# cslr_emac register map
Vendor: Texas Instruments
Peripheral module from a debugger description file (folder tci6486).
Registers are 32-bit, read-write, reset 0x0 unless marked. A register's access mark holds for its fields unless they carry their own. Offsets are as the file gives them; lines under a group give offsets from that group; [hi:lo] are bit positions; {n}, {i} and the like mark numbered series; 'fields as' and 'values as' point back to an identical list; <NAME> marks a mode.

## EMAC — Ethernet Media Access Controller
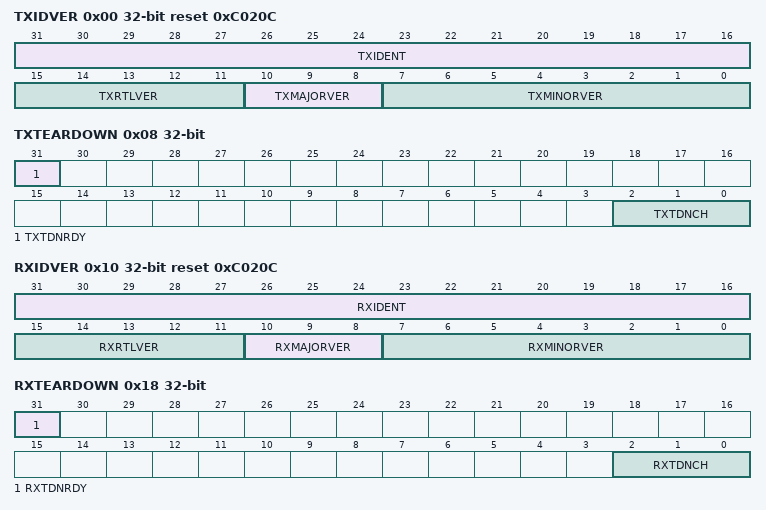
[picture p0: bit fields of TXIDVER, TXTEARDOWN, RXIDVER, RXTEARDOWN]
0x00 TXIDVER ro reset 0xC020C — Transmit Identification and Version Register
  [31:16] TXIDENT — Transmit identification value
  [15:11] TXRTLVER — Transmit RTL version value
  [10:8] TXMAJORVER — Transmit major version value
  [7:0] TXMINORVER — Transmit minor version value
0x04 TXCONTROL access not given — Transmit Control Register
  [0] TXEN rw — Transmit enable
    0=DISABLE (Transmit is disabled); 1=ENABLE (Transmit is enabled)
0x08 TXTEARDOWN access not given — Transmit Teardown Register
  [31] TXTDNRDY ro — Transmit Teardown Ready  read as zero but always assumed to be one (unused).
  [2:0] TXTDNCH rw — Transmit teardown channel. Transmit channel teardown is commanded by writing the encoded value of the transmit channel to be torn down. The teardown register is read as zero.
    {v}=CHA{v} (Teardown transmit channel {v}) (v=0..7)
0x10 RXIDVER ro reset 0xC020C — Receive Identification and Version Register
  [31:16] RXIDENT — Receive identification value
  [15:11] RXRTLVER — Receive RTL version value
  [10:8] RXMAJORVER — Receive major version value
  [7:0] RXMINORVER — Receive minor version value
0x14 RXCONTROL access not given — Receive Control Register
  [0] RXEN rw — Receive DMA enable
    0=DISABLE (Receive is disabled); 1=ENABLE (Receive is enabled)
0x18 RXTEARDOWN access not given — Receive Teardown Register
  [31] RXTDNRDY ro — Receive Teardown Ready. Read as zero, but always assumed to be one (unused)
  [2:0] RXTDNCH rw — Receive teardown channel. Receive channel teardown is commanded by writing the encoded value of the receive channel to be torn down. The teardown register is read as zero.
    {v}=CHA{v} (Teardown receive channel {v}) (v=0..7)
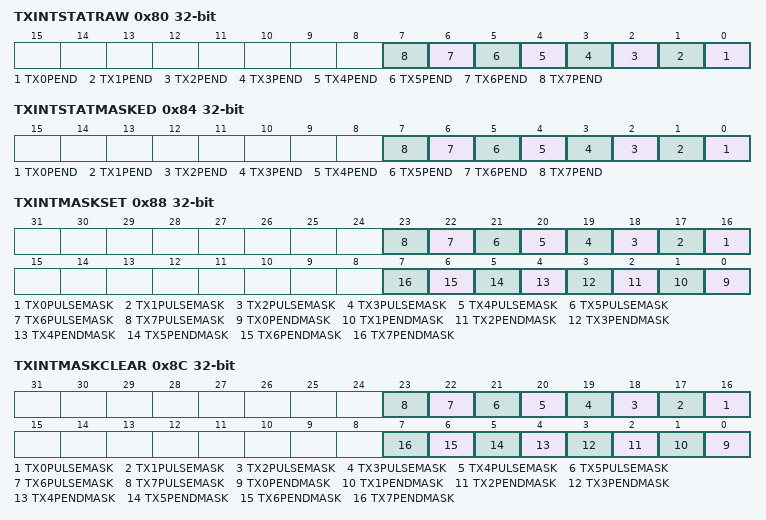
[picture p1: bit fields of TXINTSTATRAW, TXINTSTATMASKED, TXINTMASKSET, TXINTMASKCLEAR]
0x80 TXINTSTATRAW access not given — Transmit Interrupt Status (Unmasked) Register
  [n] TX{n}PEND ro (n=0..7) — TX{n}PEND raw interrupt read (before mask)
0x84 TXINTSTATMASKED access not given — Transmit Interrupt Status (Masked) Register
  [n] TX{n}PEND ro (n=0..7) — TX{n}PEND masked interrupt read
0x88 TXINTMASKSET access not given — Transmit Interrupt Mask Set Register
  [n+16] TX{n}PULSEMASK (n=0..7) — Transmit channel {n} pulse interrupt mask set bit. Write 1 to enable interrupt, a write of 0 has no effect. (access RWS)
  [n] TX{n}PENDMASK (n=0..7) — Transmit channel {n} pending interrupt mask set bit. Write 1 to enable interrupt, a write of 0 has no effect. (access RWS)
0x8C TXINTMASKCLEAR access not given — Transmit Interrupt Clear Register
  [n+16] TX{n}PULSEMASK (n=0..7) — Transmit channel {n} pulse interrupt mask clear bit. Write 1 to disable interrupt, a write of 0 has no effect. (access RWS)
  [n] TX{n}PENDMASK (n=0..7) — Transmit channel {n} pending interrupt mask clear bit. Write 1 to disable interrupt, a write of 0 has no effect. (access RWS)
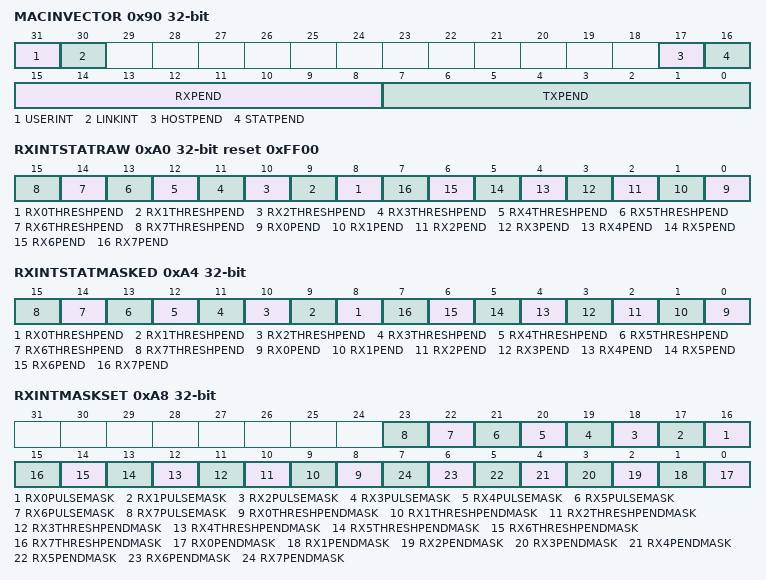
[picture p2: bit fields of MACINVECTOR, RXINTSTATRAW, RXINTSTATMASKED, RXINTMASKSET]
0x90 MACINVECTOR access not given — MAC Input Vector Register
  [31] USERINT ro — MDIO module user interrupt (USERINT) pending status bit
  [30] LINKINT ro — MDIO module link change interrupt (LINKINT) pending status bit
  [17] HOSTPEND ro — EMAC module host error interrupt (HOSTPEND) pending status bit
  [16] STATPEND ro — EMAC module statistics interrupt (STATPEND) pending status bit
  [15:8] RXPEND ro — Receive channels 0-7 interrupt (RXxPEND) pending status bit. Bit 8 is receive channel 0.
  [7:0] TXPEND ro — Transmit channels 0-7 interrupt (TXxPEND) pending status bit. Bit 0 is transmit channel 0.
0x94 MACEOIVECTOR access not given — MAC End of Interrupt Vector Register
  [4:0] MACEOIVECT rw — MAC End of Interrupt Vector  The MACEOIVECT(4:0) pins reflect the value written to this location one VBUSP_CLK cycle after write to this location. The EOI_WR signal is asserted for a single clock cycle after a a latency of two VBUSP_CLK cycle when a write is performed to this location.
0xA0 RXINTSTATRAW access not given reset 0xFF00 — Receive Interrupt Status (Unmasked) Register
  [n+8] RX{n}THRESHPEND ro (n=0..7) — RX{n}THRESHPEND raw interrupt read (before mask)
  [n] RX{n}PEND ro (n=0..7) — RX{n}PEND raw interrupt read (before mask)
0xA4 RXINTSTATMASKED access not given — Receive Interrupt Status (Masked) Register
  [n+8] RX{n}THRESHPEND ro (n=0..7) — RX{n}THRESHPEND masked interrupt read
  [n] RX{n}PEND ro (n=0..7) — RX{n}PEND masked interrupt read
0xA8 RXINTMASKSET access not given — Receive Interrupt Mask Set Register
  [n+16] RX{n}PULSEMASK (n=0..7) — Receive channel {n} Pulse Int. Mask. Write 1 to enable interrupt, a write of 0 has no effect. (access RWS)
  [n+8] RX{n}THRESHPENDMASK (n=0..7) — Receive channel {n} Threshold pending Int. Mask. Write 1 to enable interrupt, a write of 0 has no effect. (access RWS)
  [n] RX{n}PENDMASK (n=0..7) — Receive channel {n} Pending Int. Mask. Write 1 to enable interrupt, a write of 0 has no effect. (access RWS)
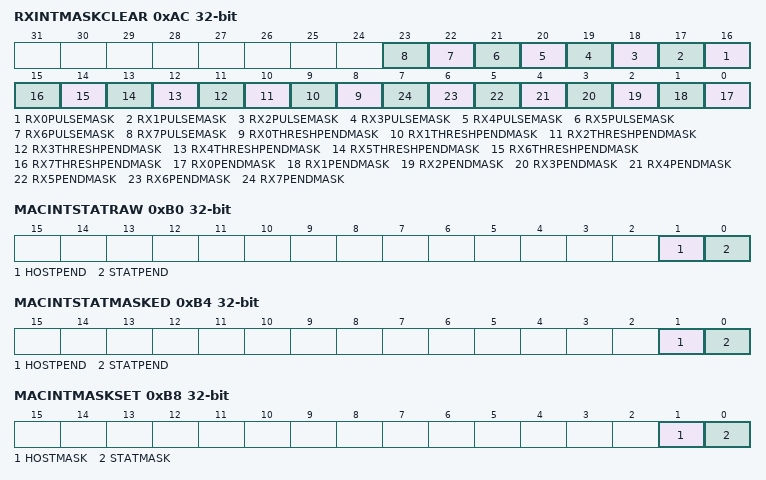
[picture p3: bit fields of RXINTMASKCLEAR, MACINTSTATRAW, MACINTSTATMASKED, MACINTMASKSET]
0xAC RXINTMASKCLEAR access not given — Receive Interrupt Mask Clear Register
  [n+16] RX{n}PULSEMASK (n=0..7) — Receive channel {n} Pulse Int. Mask. Write 1 to disable interrupt, a write of 0 has no effect. (access RWS)
  [n+8] RX{n}THRESHPENDMASK (n=0..7) — Receive channel {n} Threshold pending Int. Mask. Write 1 to disable interrupt, a write of 0 has no effect. (access RWS)
  [n] RX{n}PENDMASK (n=0..7) — Receive channel {n} Pending Int. Mask. Write 1 to disable interrupt, a write of 0 has no effect. (access RWC)
0xB0 MACINTSTATRAW access not given — MAC Interrupt Status (Unmasked) Register
  [1] HOSTPEND ro — Host pending interrupt; raw interrupt read (before mask)
  [0] STATPEND ro — Statistics pending interrupt; raw interrupt read (before mask)
0xB4 MACINTSTATMASKED access not given — MAC Interrupt Status (Masked) Register
  [1] HOSTPEND ro — Host pending interrupt; masked interrupt read
  [0] STATPEND ro — Statistics pending interrupt; masked interrupt read
0xB8 MACINTMASKSET access not given — MAC Interrupt Mask Set Register
  [1] HOSTMASK — Host error interrupt mask set bit. Write 1 to enable interrupt, a write of 0 has no effect. (access RWS)
  [0] STATMASK — Statistics interrupt mask set bit. Write 1 to enable interrupt, a write of 0 has no effect. (access RWS)
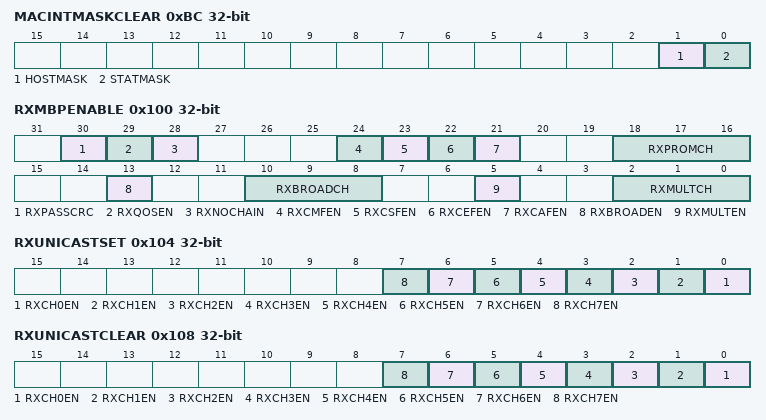
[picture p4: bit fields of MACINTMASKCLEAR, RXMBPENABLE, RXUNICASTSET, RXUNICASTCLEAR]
0xBC MACINTMASKCLEAR access not given — MAC Interrupt Mask Clear Register
  [1] HOSTMASK — Host error interrupt mask clear bit. Write 1 to disable interrupt, a write of 0 has no effect. (access RWC)
  [0] STATMASK — Statistics interrupt mask clear bit. Write 1 to disable interrupt, a write of 0 has no effect. (access RWC)
0x100 RXMBPENABLE access not given — Receive Multicast/Broadcast/Promiscuous Channel Enable Register
  [30] RXPASSCRC rw — Pass receive CRC enable bit
    0=DISCARD (Received CRC is discarded for all channels and is not included in the buffer descriptor packet length field); 1=INCLUDE (Received CRC is transferred to memory for all channels and is included in the buffer descriptor packet length)
  [29] RXQOSEN rw — Receive quality of service enable bit
    0=DISABLE (Receive QOS is disabled); 1=ENABLE (Receive QOS is enabled)
  [28] RXNOCHAIN rw — Receive no buffer chaining bit
    0=DISABLE (Received frames can span multiple buffers); 1=ENABLE (Receive DMA controller transfers each frame into a single buffer regardless of the frame or buffer size. All remaining frame data after the first buffer is discarded. The buffer descriptor)
  [24] RXCMFEN rw — Receive copy MAC control frames enable bit. Enables MAC control frames to be transferred to memory. MAC control frames are normally acted upon (if enabled), but not copied to memory. MAC control frames that are pause frames will be acted upon if enabled in MACCONTROL, regardless of the value of RXCMFEN. Frames transferred to memory due to RXCMFEN will have the CONTROL bit set in their EOP buffer descriptor.
    0=DISABLE (MAC control frames are filtered (but acted upon if enabled)); 1=ENABLE (MAC control frames are transferred to memory)
  [23] RXCSFEN rw — Receive copy short frames enable bit. Enables frames or fragments shorter than 64 bytes to be copied to memory. Frames transferred to memory due to RXCSFEN will have the FRAGMENT or UNDERSIZE bit set in their EOP buffer descriptor. Fragments are short frames that contain CRC/align/code errors and undersized are short frames without errors.
    0=DISABLE (Short frames are filtered); 1=ENABLE (Short frames are transferred to memory)
  [22] RXCEFEN rw — Receive copy error frames enable bit. Enables frames containing errors to be transferred to memory. The appropriate error bit will be set in the frame EOP buffer descriptor.
    0=DISABLE (Frames containing errors are filtered); 1=ENABLE (Frames containing errors are transferred to memory)
  [21] RXCAFEN rw — Receive copy all frames enable bit. Enables frames that do not address match (includes multicast frames that do not hash match) to be transferred to the promiscuous channel selected by RXPROMCH bits. Such frames will be marked with the NOMATCH bit in their EOP buffer descriptor.
    0=DISABLE (Frames that do not address match are filtered); 1=ENABLE (Frames that do not address match are transferred to the promiscuous channel selected by RXPROMCH bits)
  [18:16] RXPROMCH rw — Receive promiscuous channel select
    {v}=CHA{v} (Select channel {v} to receive promiscuous frames) (v=0..7)
  [13] RXBROADEN rw — Receive broadcast enable. Enable received broadcast frames to be copied to the channel selected by RXBROADCH bits.
    0=DISABLE (Broadcast frames are filtered); 1=ENABLE (Broadcast frames are copied to the channel selected by RXBROADCH bits)
  [10:8] RXBROADCH rw — Receive broadcast channel select
    0=CHA0 (Select channel 0 to receive broadcast frames); 1=CHA1 (Select channel 1 to receive broadcast frames); 2=CHA2 (Select channel 2 to receive promiscuous frames); {v}=CHA{v} (Select channel {v} to receive broadcast frames) (v=3..7)
  [5] RXMULTEN rw — RX multicast enable. Enable received hash matching multicast frames to be copied to the channel selected by RXMULTCH bits.
    0=DISABLE (Multicast frames are filtered); 1=ENABLE (Multicast frames are copied to the channel selected by RXMULTCH bits)
  [2:0] RXMULTCH rw — Receive multicast channel select
    0=CHA0 (Select channel 0 to receive multicast frames); 1=CHA1 (Select channel 1 to receive multicast frames); 2=CHA2 (Select channel 2 to receive promiscuous frames); {v}=CHA{v} (Select channel {v} to receive multicast frames) (v=3..7)
0x104 RXUNICASTSET access not given — Receive Unicast Enable Set Register
  [n] RXCH{n}EN (n=0..7) — Receive channel {n} unicast enable set bit. Write 1 to set the enable, a write of 0 has no effect. May be read. (access RWS)
0x108 RXUNICASTCLEAR access not given — Receive Unicast Clear Register
  [n] RXCH{n}EN (n=0..7) — Receive channel {n} unicast enable clear bit. Write 1 to clear the enable, a write of 0 has no effect. (access RWC)
0x10C RXMAXLEN access not given reset 0x1518 — Receive Maximum Length Register
  [15:0] RXMAXLEN rw — Receive maximum frame length. These bits determine the maximum length of a received frame. The reset value is 5EEh (1518). Frames with byte counts greater than RXMAXLEN are long frames. Long frames with no errors are oversized frames. Long frames with CRC, code, or alignment error are jabber frames.
0x110 RXBUFFEROFFSET access not given — Receive Buffer Offset Register
  [15:0] RXBUFFEROFFSET rw — Receive buffer offset value. These bits are written by the EMAC into each frame SOP buffer descriptor Buffer Offset field. The frame data begins after the RXBUFFEROFFSET value of bytes. A value of 0 indicates that there are no unused bytes at the beginning of the data and that valid data begins on the first byte of the buffer. A value of Fh (15) indicates that the first 15 bytes of the buffer are to be ignored by the EMAC and that valid buffer data starts on byte 16 of the buffer. This value is used for all channels.
0x114 RXFILTERLOWTHRESH access not given — Receive Filter Low Priority Frame Threshold Register
  [7:0] RXFILTERTHRESH rw — Receive filter low threshold. These bits contain the receive channel n free buffer count register (RXnFREEBUFFER) threshold value for filtering low priority incoming frames. This field should remain zero, if no filtering is desired.
{0x120+4i} RX{i}FLOWTHRESH access not given (i=0..7) — Receive Channel {i} Flow Control Threshold Register
  [7:0] RX{i}FLOWTHRESH rw — Receive flow threshold. These bits contain the threshold value for issuing flow control on incoming frames (when enabled).
{0x140+4i} RX{i}FREEBUFFER access not given (i=0..7) — Receive Channel {i} Free Buffer Count Register
  [15:0] RX{i}FREEBUF — Receive free buffer count. These bits contain the count of free buffers available. The RXFILTERTHRESH value is compared with this field to determine if low priority frames should be filtered. The RX{i}FLOWTHRESH value is compared with this field to determine if receive flow control should be issued against incoming packets (if enabled). This is a write-to-increment field. This field rolls over to zero on overflow. If hardware flow control or QOS is used, the host must initialize this field to the number of available buffers (one register per channel). The EMAC decrements (by the number of buffers in the received frame) the associated channel register for each received frame. The host must write this field with the number of buffers that have been freed due to host processing. (access WI)
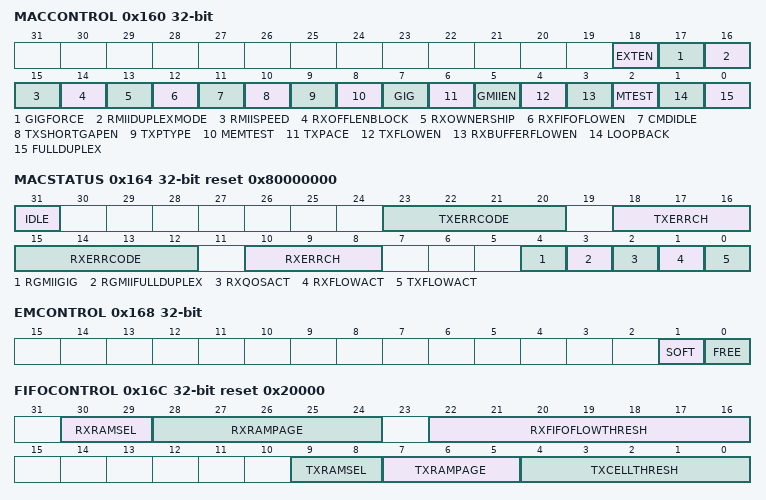
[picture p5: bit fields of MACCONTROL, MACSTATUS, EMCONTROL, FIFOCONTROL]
0x160 MACCONTROL access not given
  [18] EXTEN rw — External enable  enbles the fullduplex and gigabit mode to be selected from the EXT_FULLDUPLEX and EXT_GIG input signals and not from the full duplex and gig bits contained in this register. This register bit is also output on the EXT_EN signal.
  [17] GIGFORCE rw — Gigabit force mode. This bit is used to force the EMAC into gigabit mode if the input MTCLK signal has been stopped by the PHY.
  [16] RMIIDUPLEXMODE rw — Duplex mode for the RMII interface
    0=HALFDUPLEX (The RMII operates in half duplex mode); 1=FULLDUPLEX (The RMII operates in full duplex mode)
  [15] RMIISPEED rw — Operating speed for the RMII interface
    0=2_5MHZ (The RMII operates at 2.5 MHz); 1=25MHZ (The RMII operates at 25 MHz)
  [14] RXOFFLENBLOCK rw — Receive offset / length word write block
    0=NOBLOCK (Do not block the DMA writes to the receive buffer descriptor offset/buffer length word); 1=BLOCK (Block all EMAC DMA controller writes to the receive buffer descriptor offset/buffer length words during packet processing. When this bit is set, the EMAC will never write the third word to any receive buffer descriptor)
  [13] RXOWNERSHIP rw — Receive ownership write bit value
    0=ZERO (The EMAC writes the Receive ownership bit to zero at the end of packet processing); 1=ONE (The EMAC writes the Receive ownership bit to one at the end of packet processing)
  [12] RXFIFOFLOWEN rw — Receive FIFO flow control enable
    0=DISABLE (Receive flow control disabled. For full-duplex mode, no outgoing pause frames are sent); 1=ENABLE (Receive flow control enabled. For full-duplex mode, outgoing pause frames are sent when receive FIFO flow control is triggered)
  [11] CMDIDLE rw — Command Idle bit
    0=DISABLE (Idle not commanded); 1=ENABLE (Idle commanded (read IDLE in the MACSTATUS register))
  [10] TXSHORTGAPEN rw — Transmit short gap enable
    0=DISABLE (Transmit with short IPG is disabled); 1=ENABLE (Transmit with short IPG (when TX_SHORT_GAP input asserted ) is enabled.)
  [9] TXPTYPE rw — Transmit queue priority type
    0=RROBIN (The queue uses a round-robin scheme to select the next channel for transmission); 1=CHANNELPRI (The queue uses a fixed-priority (channel 7 highest priority) scheme to select the next channel for transmission)
  [8] MEMTEST rw — FIFO RAM processor read/write Enable
    0=NOHOSTACCESS (No Host access to RX/TX FIFO RAM); 1=HOSTACCESS (Host read/write access to RX/TX FIFO RAM)
  [7] GIG rw — Gigabit mode
    0=DISABLE (Gigabit mode is disabled; 10/100 mode is in operation); 1=ENABLE (Gigabit mode is enabled (full-duplex only))
  [6] TXPACE rw — Transmit pacing enable bit
    0=DISABLE (Transmit pacing is disabled); 1=ENABLE (Transmit pacing is enabled)
  [5] GMIIEN rw — GMII enable bit
    0=DISABLE (GMII RX and TX are held in reset); 1=ENABLE (GMII RX and TX are enabled for receive and transmit)
  [4] TXFLOWEN rw — Transmit flow control enable bit. This bit determines if incoming pause frames are acted upon in full-duplex mode. Incoming pause frames are not acted upon in half-duplex mode, regardless of this bit setting. The RXMBPENABLE bits determine whether or not received pause frames are transferred to memory.
    0=DISABLE (Transmit flow control is disabled. Full-duplex mode: incoming pause frames are not acted upon); 1=ENABLE (Transmit flow control is enabled. Full-duplex mode: incoming pause frames are acted upon)
  [3] RXBUFFERFLOWEN rw — Receive buffer flow control enable bit
    0=DISABLE (Receive flow control is disabled. Half-duplex mode: no flow control generated collisions are sent. Full-duplex mode: no outgoing pause frames are sent); 1=ENABLE (Receive flow control is enabled. Half-duplex mode: collisions are initiated when receive buffer flow control is triggered. Full-duplex mode: outgoing pause frames are sent when receive flow control is triggered)
  [2] MTEST rw — Manufacturing Test Mode  This bit must be set to allow writes to the Backoff_Test and PulseTimer registers.
  [1] LOOPBACK rw — Loopback mode. The loopback mode forces internal full-duplex mode regardless of the FULLDUPLEX bit. The loopback bit should be changed only when GMIIEN bit is deasserted.
    0=DISABLE (Loopback mode is disabled); 1=ENABLE (Loopback mode is enabled)
  [0] FULLDUPLEX rw — Full duplex mode. The gigabit mode forces full duplex mode regardless of whether the FULLDUPLEX bit is set or not.
    0=DISABLE (Half-duplex mode is enabled); 1=ENABLE (Full-duplex mode is enabled)
0x164 MACSTATUS access not given reset 0x80000000
  [31] IDLE ro — EMAC idle bit. This bit is set to 0 at reset; one clock after reset it goes to 1.
    0=NOIDLE (The EMAC is not idle); 1=IDLE (The EMAC is in the idle state)
  [23:20] TXERRCODE ro — Transmit host error code. These bits indicate that EMAC detected transmit DMA related host errors. The host should read this field after a host error interrupt (HOSTPEND) to determine the error. Host error interrupts require hardware reset in order to recover. A zero packet length is an error, but it is not detected
    0=NOERROR; 1=SOPERROR (SOP error; the buffer is the first buffer in a packet, but the SOP bit is not set in software.); 2=OWNERSHIP (Ownership bit not set in SOP buffer); 3=NOEOP (Zero next buffer descriptor pointer without EOP); 4=NULLPTR (Zero buffer pointer); 5=NULLEN (Zero buffer length); 6=LENRRROR (Packet length error (sum of buffers < packet length))
  [18:16] TXERRCH ro — Transmit host error channel. These bits indicate which transmit channel the host error occurred on. This field is cleared to 0 on a host read.
    {v}=CHA{v} (The host error occurred on transmit channel {v}) (v=0..7)
  [15:12] RXERRCODE ro — Receive host error code. These bits indicate that EMAC detected receive DMA related host errors. The host should read this field after a host error interrupt (HOSTPEND) to determine the error. Host error interrupts require hardware reset in order to recover.
    0=NOERROR; 2=OWNERSHIP (Ownership bit not set in SOP buffer); 4=NULLPTR (Zero buffer pointer)
  [10:8] RXERRCH ro — Receive host error channel. These bits indicate which receive channel the host error occurred on. This field is cleared to 0 on a host read.
    {v}=CHA{v} (The host error occurred on receive channel {v}) (v=0..7)
  [4] RGMIIGIG ro — RGMII gigabit. This is the value of RGMIIGIG input.
  [3] RGMIIFULLDUPLEX ro — RGMII full-duplex. This is the value of RGMIIFULLDUPLEX input.
  [2] RXQOSACT ro — Receive Quality of Service (QOS) active bit. When asserted, indicates that receive quality of service is enabled and that at least one channel freebuffer count (RXnFREEBUFFER) is less than or equal to the RXFILTERLOWTHRESH value.
    0=DISABLE (Receive quality of service is disabled.); 1=ENABLE (Receive quality of service is enabled)
  [1] RXFLOWACT ro — Receive flow control active bit. When asserted, indicates that at least one channel freebuffer count (RXnFREEBUFFER) is less than or equal to the channel's corresponding RXnFILTERTHRESH value.
    0=INACTIVE (Receive flow control is inactive); 1=ACTIVE (Receive flow control is active)
  [0] TXFLOWACT ro — Transmit flow control active bit. When asserted, this bit indicates that the pause time period is being observed for a received pause frame. No new transmissions will begin while this bit is asserted except for the transmission of pause frames. Any transmission in progress when this bit is asserted will complete.
    0=INACTIVE (Transmit flow control is inactive); 1=ACTIVE (Transmit flow control is active)
0x168 EMCONTROL access not given — Emulation Control Register
  [1] SOFT rw — Emulation soft bit
  [0] FREE rw — Emulation free bit
0x16C FIFOCONTROL access not given reset 0x20000 (reset mask 0xFFFFFFE0)
  [30:29] RXRAMSEL rw — Receive FIFO Ram select  Determines which of the three receive rams are selected for processor read write in test mode ( memtest = 1)
    0=SRAM (Storage Ram); 1=IRAM (Info Ram); 2=DBRAM (Double Buffer Ram)
  [28:24] RXRAMPAGE rw — Receive FIFO Ram page  Determines which storage Ram page is accessed in test mode (memset = 1 and RXRAMSEL = 0)
  [22:16] RXFIFOFLOWTHRESH rw — Receive FIFO flow control threshold. Occupancy of the receive FIFO when Receive FIFO control is triggered (if enabled). The default value is 0x2 which means that receive FIFO flow control will be triggered when the occupancy of the FIFO reaches two cells.
  [9:8] TXRAMSEL rw — Transmit FIFO Ram Select  Determines which of the three transmit FIFO Rams are selected for processor read write int test mode ( memtest = 1)
    values as RXRAMSEL
  [7:5] TXRAMPAGE rw — Transmit FIFO RAM Page  Determines which of the Storage ram page is accessed in test mode (memtest = 1 and TXRAMSEL = 0)
  [4:0] TXCELLTHRESH rw — Transmit FIFO cell threshold. Indicates the number of 64-byte packet cells required to be in the transmit FIFO before the packet transfer is initiated. Packets with fewer cells will be initiated when the complete packet is contained in the FIFO.
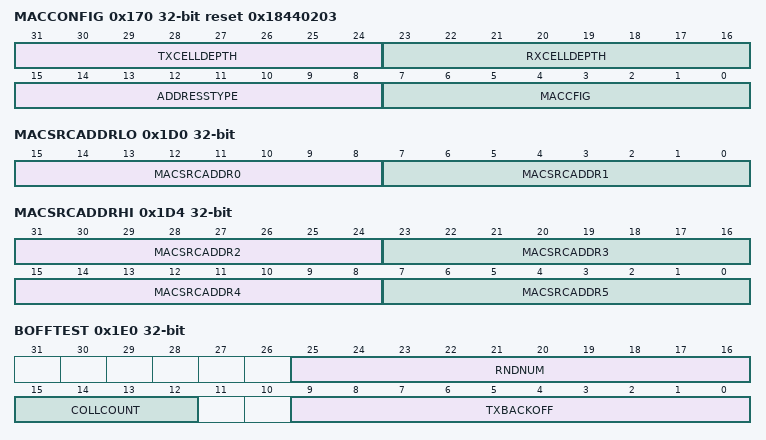
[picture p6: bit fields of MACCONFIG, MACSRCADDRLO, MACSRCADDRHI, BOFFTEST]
0x170 MACCONFIG ro reset 0x18440203 — MAC Configuration Register
  [31:24] TXCELLDEPTH — Transmit cell depth. These bit indicates the number of cells in the transmit FIFO.
  [23:16] RXCELLDEPTH — Receive cell depth. These bits indicate the number of cells in the receive FIFO.
  [15:8] ADDRESSTYPE
  [7:0] MACCFIG — MAC configuration value
0x174 SOFTRESET access not given
  [0] SOFTRESET rw — Software reset. Writing a one to this bit causes the EMAC logic to be reset. Software reset occurs when the receive and transmit DMA controllers are in an idle state to avoid locking up the Configuration bus. After writing a one to this bit, it may be polled to determine if the reset has occurred. If a one is read, the reset has not yet occurred. If a zero is read then reset has occurred.
    0=NORESET (A software reset has not occurred); 1=RESET (A software reset has occurred)
0x1D0 MACSRCADDRLO access not given — MAC Source Address Low Bytes Register
  [15:8] MACSRCADDR0 rw — MAC source address lower 8 bits (byte 0)
  [7:0] MACSRCADDR1 rw — MAC source address bits 15-9 (byte 1)
0x1D4 MACSRCADDRHI — MAC Source Address High Bytes Register
  [31:24] MACSRCADDR2 — MAC source address bits 23-16 (byte 2)
  [23:16] MACSRCADDR3 — MAC source address bits 31-23 (byte 3)
  [15:8] MACSRCADDR4 — MAC source address bits 39-32 (byte 4)
  [7:0] MACSRCADDR5 — MAC source address bits 47-40 (byte 5)
0x1D8 MACHASH1 — MAC Hash Address Register 1
  [31:0] MACHASH1 — Least-significant 32 bits of the hash table corresponding to hash values 0 to 31. If a hash table bit is set, then a group address that hashes to that bit index is accepted.
0x1DC MACHASH2 — MAC Hash Address Register 2
  [31:0] MACHASH2 — Most-significant 32 bits of the hash table corresponding to hash values 32 to 63. If a hash table bit is set, then a group address that hashes to that bit index is accepted.
0x1E0 BOFFTEST access not given — Back Off Test Register
  [25:16] RNDNUM ro — Backoff random number generator. This field allows the Backoff Random Number Generator to be read. Reading this field returns the generator's current value. The value is reset to zero and begins counting on the clock after the deassertion of reset.
  [15:12] COLLCOUNT ro — Collision count. These bits indicate the number of collisions the current frame has experienced.
  [9:0] TXBACKOFF ro — Backoff count. This field allows the current value of the backoff counter to be observed for test purposes. This field is loaded automatically according to the backoff algorithm, and is decremented by one for each slot time after the collision.
0x1E4 TPACETEST access not given — Transmit Pacing Algorithm Test Register
  [4:0] PACEVAL ro — Pacing register current value. A nonzero value in this field indicates that transmit pacing is active. A transmit frame collision or deferral causes PACEVAL to be loaded with 1Fh (31); good frame transmissions (with no collisions or deferrals) cause PACEVAL to be decremented down to 0. When PACEVAL is nonzero, the transmitter delays four Inter Packet Gaps between new frame transmissions after each successfully transmitted frame that had no deferrals or collisions. If a transmit frame is deferred or suffers a collision, the IPG time is not stretched to four times the normal value. Transmit pacing helps reduce capture effects, which improves overall network bandwidth.
0x1E8 RXPAUSE access not given — Receive Pause Timer Register
  [15:0] PAUSETIMER ro — Receive pause timer value. These bits allow the contents of the receive pause timer to be observed. The receive pause timer is loaded with FF00h when the EMAC sends an outgoing pause frame (with pause time of FFFFh). The receive pause timer is decremented at slot time intervals. If the receive pause timer decrements to 0, then another outgoing pause frame is sent and the load/decrement process is repeated.
0x1EC TXPAUSE access not given — Transmit Pause Timer Register
  [15:0] PAUSETIMER ro — Transmit pause timer value. These bits allow the contents of the transmit pause timer to be observed. The transmit pause timer is loaded by a received (incoming) pause frame, and then decremented at slot time intervals down to 0 at which time EMAC transmit frames are again enabled.
0x200 RXGOODFRAMES — Good Receive Frames
  [31:0] COUNT
0x204 RXBCASTFRAMES — Total number of good broadcast frames received
  [31:0] COUNT
0x208 RXMCASTFRAMES — Total number of good multicast frames received
  [31:0] COUNT
0x20C RXPAUSEFRAMES — Pause Receive Frames Register
  [31:0] COUNT
0x210 RXCRCERRORS — Total number of frames received with CRC errors
  [31:0] COUNT
0x214 RXALIGNCODEERRORS — Total number of frames received with alignment/code errors
  [31:0] COUNT
0x218 RXOVERSIZED — Total number of oversized frames received
  [31:0] COUNT
0x21C RXJABBER — Total number of jabber frames received
  [31:0] COUNT
0x220 RXUNDERSIZED — Total number of undersized frames received
  [31:0] COUNT
0x224 RXFRAGMENTS — Receive Frame Fragments Register
  [31:0] COUNT
0x228 RXFILTERED — Filtered Receive Frames
  [31:0] COUNT
0x22C RXQOSFILTERED — Received Frames Filtered by QOS
  [31:0] COUNT
0x230 RXOCTETS — Total number of received bytes in good frames
  [31:0] COUNT
0x234 TXGOODFRAMES — Total number of good frames transmitted
  [31:0] COUNT
0x238 TXBCASTFRAMES — Broadcast Transmit Frames Register
  [31:0] COUNT
0x23C TXMCASTFRAMES — Multicast Transmit Frames Register
  [31:0] COUNT
0x240 TXPAUSEFRAMES — Pause Transmit Frames Register
  [31:0] COUNT
0x244 TXDEFERRED — Deferred Transmit Frames Register
  [31:0] COUNT
0x248 TXCOLLISION — Transmit Collision Frames Register
  [31:0] COUNT
0x24C TXSINGLECOLL — Transmit Single Collision Frames Register
  [31:0] COUNT
0x250 TXMULTICOLL — Transmit Multiple Collision Frames Register
  [31:0] COUNT
0x254 TXEXCESSIVECOLL — Transmit Excessive Collision Frames Register
  [31:0] COUNT
0x258 TXLATECOLL — Transmit Late Collision Frames Register
  [31:0] COUNT
0x25C TXUNDERRUN — Transmit Underrun Error Register
  [31:0] COUNT
0x260 TXCARRIERSENSE — Transmit Carrier Sense Errors Register
  [31:0] COUNT
0x264 TXOCTETS — Transmit Octet Frames Register
  [31:0] COUNT
0x268 FRAME64 — Transmit and Receive 64 Octet Frames Register
  [31:0] COUNT
0x26C FRAME65T127 — Transmit and Receive 65 to 127 Octet Frames Register
  [31:0] COUNT
0x270 FRAME128T255 — Transmit and Receive 128 to 255 Octet Frames Register
  [31:0] COUNT
0x274 FRAME256T511 — Transmit and Receive 256 to 511 Octet Frames Register
  [31:0] COUNT
0x278 FRAME512T1023 — Transmit and Receive 512 to 1023 Octet Frames Register
  [31:0] COUNT
0x27C FRAME1024TUP — Transmit and Receive 1024 to 1518 Octet Frames Register
  [31:0] COUNT
0x280 NETOCTETS — Network Octet Frames Register
  [31:0] COUNT
0x284 RXSOFOVERRUNS — Receive FIFO or DMA Start of Frame Overruns Register
  [31:0] COUNT
0x288 RXMOFOVERRUNS — Receive FIFO or DMA Middle of Frame Overruns Register
  [31:0] COUNT
0x28C RXDMAOVERRUNS — Receive DMA Start of Frame and Middle of Frame Overruns Register
  [31:0] COUNT
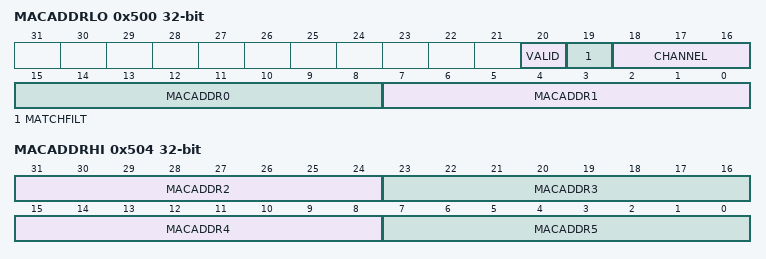
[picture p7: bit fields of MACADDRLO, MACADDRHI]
0x500 MACADDRLO access not given — MAC Address Low Bytes Register, Used in Receive Address Matching
  [20] VALID rw — Address valid bit. This bit should be cleared to zero for unused address RAM locations.
    0=INVALID (Address location is not valid and will not be used in determinig whether or not an incoming packet matches or is filtered); 1=VALID (Address location is valid and will be used in determinig whether or not an incoming packet matches or is filtered)
  [19] MATCHFILT rw — Match or filter bit
    0=FILTER (The address will be used (if VALID is set) to determine if the incoming packet address should be filtered); 1=MATCH (The address will be used (if VALID is set) to determine if the incoming packet address is a match)
  [18:16] CHANNEL rw — Channel bit; determines which receive channel a valid address match will be transferred to. The channel is a don't care if the MATCHFILT bit is cleared to zero.
  [15:8] MACADDR0 rw — MAC addres lower 8 bits (byte 0)
  [7:0] MACADDR1 rw — MAC addres bits 15-8 (byte 1)
0x504 MACADDRHI — MAC Address High Bytes Register, Used in Receive Address Matching
  [31:24] MACADDR2 — MAC source address bits 23-16 (byte 2)
  [23:16] MACADDR3 — MAC source address bits 31-23 (byte 3)
  [15:8] MACADDR4 — MAC source address bits 39-32 (byte 4)
  [7:0] MACADDR5 — MAC source address bits 47-40 (byte 5)
0x508 MACINDEX access not given
  [4:0] MACINDEX rw — MAC address index. The host must write the index into the RX ADDR RAM in the MACINDEX field, followed by the upper 32-bits of address, followed by the lower 16-bits of address (with control bits). The 53-bit indexed ram location is written when the low location is written. All 32 address RAM locations must be initialized prior to enabling packet reception.
{0x600+4i} TX{i}HDP (i=0..5) — Transmit Channel {i} DMA Head Descriptor Pointer Register
  [31:0] TX{i}HDP — Transmit channel {i} DMA Head Descriptor pointer. Writing a transmit DMA buffer descriptor address to a head pointer location initiates transmit DMA operations in the queue for the selected channel. Writing to these locations when they are nonzero is an error (except at reset). Host software must initialize these locations to zero on reset.
0x618 TX6HDP — Transmit Channel 6 DMA Head Descriptor Pointer Register
  [31:0] TX6HDP — Transmit channel 6 DMA Head Descriptor pointer
0x61C TX7HDP — Transmit Channel 7 DMA Head Descriptor Pointer Register
  [31:0] TX7HDP — Transmit channel 7 DMA Head Descriptor pointer. Writing a transmit DMA buffer descriptor address to a head pointer location initiates transmit DMA operations in the queue for the selected channel. Writing to these locations when they are nonzero is an error (except at reset). Host software must initialize these locations to zero on reset.
0x620 RX0HDP — Receive Channel 0 DMA Head Descriptor Pointer Register
  [31:0] RX0HDP — Receive channel 0 DMA Head Descriptor pointer. Writing a receive DMA buffer descriptor address to this location allows receive DMA operations in the selected channel when a channel frame is received. Writing to these locations when they are nonzero is an error (except at reset). Host software must initialize these locations to zero on reset.
0x624 RX1HDP — Receive Channel 1 DMA Head Descriptor Pointer Register
  [31:0] RX1HDP — Receive channel 1 DMA Head Descriptor pointer. . Writing a receive DMA buffer descriptor address to this location allows receive DMA operations in the selected channel when a channel frame is received. Writing to these locations when they are nonzero is an error (except at reset). Host software must initialize these locations to zero on reset.
{0x620+4i} RX{i}HDP (i=2..7) — Receive Channel {i} DMA Head Descriptor Pointer Register
  [31:0] RX{i}HDP — Receive channel {i} DMA Head Descriptor pointer. Writing a receive DMA buffer descriptor address to this location allows receive DMA operations in the selected channel when a channel frame is received. Writing to these locations when they are nonzero is an error (except at reset). Host software must initialize these locations to zero on reset.
0x640 TX0CP — Transmit Channel 0 Completion Pointer (Interrupt Ack) Register
  [31:0] TX0CP — Transmit channel 0 completion pointer register is written by the host with the buffer descriptor address for the last buffer processed by the host during interrupt processing. The EMAC uses the value written to determine if the interrupt should be deasserted.
{0x640+4i} TX{i}CP (i=1..7) — Transmit Channel {i} Completion Pointer Register
  [31:0] TX{i}CP — Transmit channel {i} completion pointer register is written by the host with the buffer descriptor address for the last buffer processed by the host during interrupt processing. The EMAC uses the value written to determine if the interrupt should be deasserted.
{0x660+4i} RX{i}CP (i=0..7) — Receive Channel {i} Completion Pointer (Interrupt Ack) Register
  [31:0] RX{i}CP — Receive channel {i} completion pointer register is written by the host with the buffer descriptor address for the last buffer processed by the host during interrupt processing. The EMAC uses the value written to determine if the interrupt should be deasserted.
